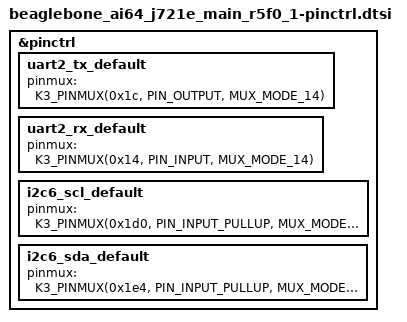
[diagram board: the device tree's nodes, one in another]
/* Copyright (C) 2023 BeagleBoard.org Foundation
 * Copyright (C) 2023 S Prashanth
 * Copyright (c) 2024 Texas Instruments Incorporated
 *	Andrew Davis <afd@ti.com>
 *
 * SPDX-License-Identifier: Apache-2.0
 */

#include <zephyr/dt-bindings/pinctrl/ti-k3-pinctrl.h>

&pinctrl {
	uart2_tx_default: uart2_tx_default {
		/* 0x1c is address of padconfig register of p8.34 and 14 is mux mode */
		pinmux = <K3_PINMUX(0x1c, PIN_OUTPUT, MUX_MODE_14)>;
		/* mux mode 14 tells that this configurable pin is configured to uart2 now*/
	};

	uart2_rx_default: uart2_rx_default {
		/* 0x14 is address of padconfig register of p8.22 and 14 is mux mode */
		pinmux = <K3_PINMUX(0x14, PIN_INPUT, MUX_MODE_14)>;
	};

	i2c6_scl_default: i2c6_scl_default {
		/* 0x1e0 is the address of padconfig register of p9.17 and 2 is mux mode */
		pinmux = <K3_PINMUX(0x1d0, PIN_INPUT_PULLUP, MUX_MODE_2)>;
	};

	i2c6_sda_default: i2c6_sda_default {
		/* 0x1dc is the address of padconfig register of p9.18 and 2 is mux mode */
		pinmux = <K3_PINMUX(0x1e4, PIN_INPUT_PULLUP, MUX_MODE_2)>;
	};
};
/* offsets are unchanged for as same type of core is used in the same cluster , probably need to see bb details to be sure ??*/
